# CH32H417 register map
Vendor: WCH Ltd.; File version: 1.2
Registers are 32-bit, read-write, reset 0x0 unless marked. A register's access mark holds for its fields unless they carry their own. Offsets are from the block's base; [hi:lo] are bit positions; {n}, {i} and the like mark numbered series; 'fields as' and 'values as' point back to an identical list.

## FMC
Base 0x40025400
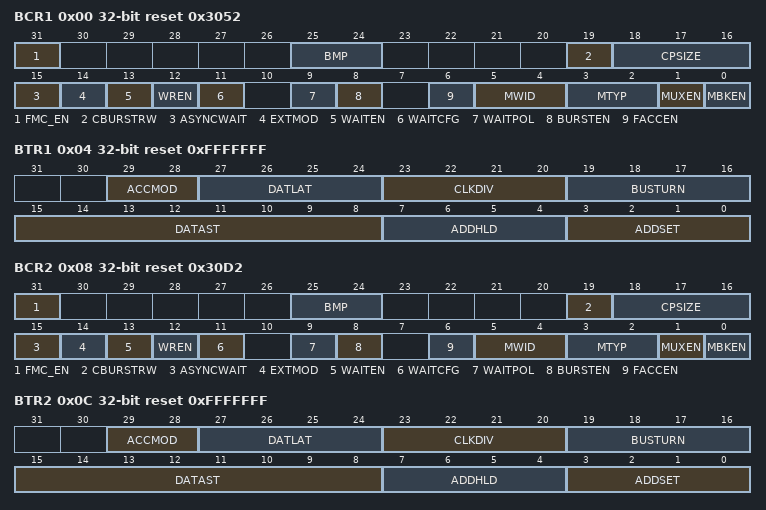
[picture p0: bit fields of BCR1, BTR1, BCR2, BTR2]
0x00 BCR1 reset 0x3052 — This register contains the control information of each memory bank, used for SRAMs, PSRAM and NOR Flash memories.
  [31] FMC_EN — FMC controller Enable
  [25:24] BMP — FMC bank mapping
  [19] CBURSTRW — Write burst enable
  [18:16] CPSIZE — CRAM Page Size
  [15] ASYNCWAIT — Wait signal during asynchronous transfers
  [14] EXTMOD — Extended mode enable
  [13] WAITEN — Wait enable bit
  [12] WREN — Write enable bit
  [11] WAITCFG — Wait timing configuration
  [9] WAITPOL — Wait signal polarity bit
  [8] BURSTEN — Burst enable bit
  [6] FACCEN — Flash access enable
  [5:4] MWID — Memory data bus width Defines the external memory device width, valid for all type of memories.
  [3:2] MTYP — Memory type
  [1] MUXEN — Address/data multiplexing enable bit
  [0] MBKEN — Memory bank enable
0x04 BTR1 reset 0xFFFFFFF — This register contains the control information of each memory bank, used for SRAMs, PSRAM and NOR Flash memories
  [29:28] ACCMOD — Access mode
  [27:24] DATLAT — Data latency for synchronous memory For synchronous access with read write burst mode enabled
  [23:20] CLKDIV — Clock divide ratio (for FMC_CLK signal)
  [19:16] BUSTURN — Bus turnaround phase duration
  [15:8] DATAST — Data-phase duration
  [7:4] ADDHLD — Address-hold phase duration
  [3:0] ADDSET — Address setup phase duration
0x08 BCR2 reset 0x30D2 — This register contains the control information of each memory bank, used for SRAMs, PSRAM and NOR Flash memories.
  [31] FMC_EN — FMC controller Enable
  [25:24] BMP — FMC bank mapping
  [19] CBURSTRW — Write burst enable For PSRAM (CRAM) operating in Burst mode
  [18:16] CPSIZE — CRAM Page Size
  [15] ASYNCWAIT — Wait signal during asynchronous transfers
  [14] EXTMOD — Extended mode enable
  [13] WAITEN — Wait enable bit
  [12] WREN — Write enable bit
  [11] WAITCFG — Wait timing configuration
  [9] WAITPOL — Wait signal polarity bit
  [8] BURSTEN — Burst enable bit
  [6] FACCEN — Flash access enable
  [5:4] MWID — Memory data bus width Defines the external memory device width, valid for all type of memories.
  [3:2] MTYP — Memory type
  [1] MUXEN — Address/data multiplexing enable bit
  [0] MBKEN — Memory bank enable bit
0x0C BTR2 reset 0xFFFFFFF — This register contains the control information of each memory bank, used for SRAMs, PSRAM and NOR Flash memories
  fields as BTR1
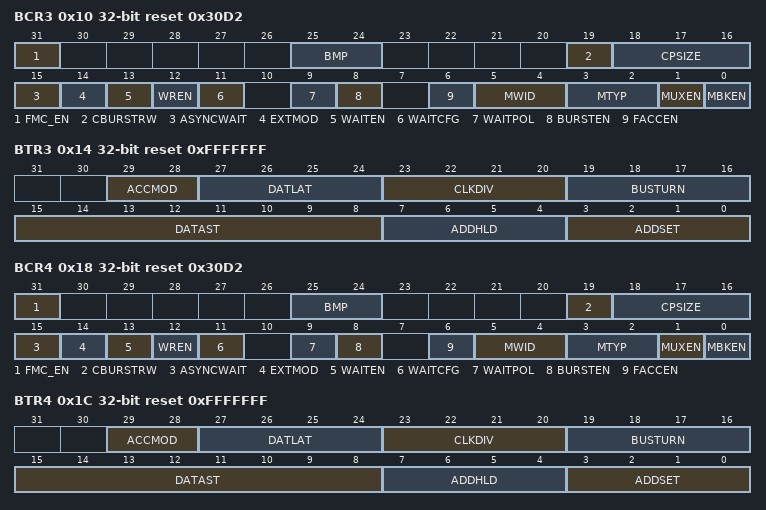
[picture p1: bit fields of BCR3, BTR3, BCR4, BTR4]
0x10 BCR3 reset 0x30D2 — This register contains the control information of each memory bank, used for SRAMs, PSRAM and NOR Flash memories.
  fields as BCR2
0x14 BTR3 reset 0xFFFFFFF — This register contains the control information of each memory bank, used for SRAMs, PSRAM and NOR Flash memories
  fields as BTR1
0x18 BCR4 reset 0x30D2 — This register contains the control information of each memory bank, used for SRAMs, PSRAM and NOR Flash memories.
  fields as BCR2
0x1C BTR4 reset 0xFFFFFFF — This register contains the control information of each memory bank, used for SRAMs, PSRAM and NOR Flash memories
  fields as BTR1
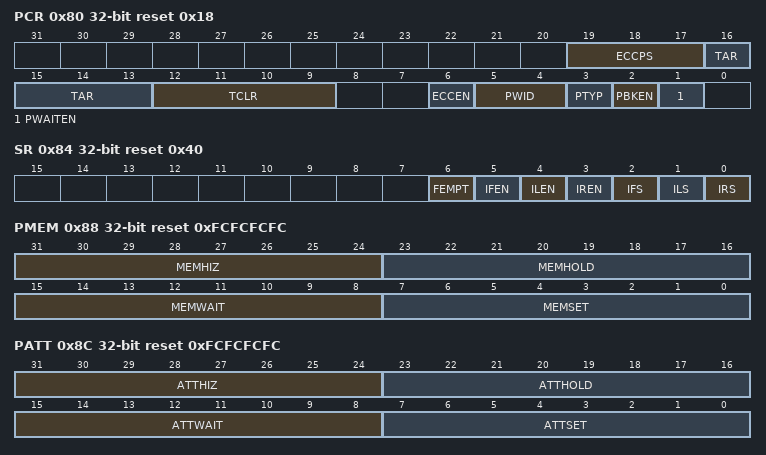
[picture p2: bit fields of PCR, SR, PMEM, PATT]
0x80 PCR reset 0x18 — NAND Flash control registers
  [19:17] ECCPS — ECC page size
  [16:13] TAR — ALE to RE delay
  [12:9] TCLR — CLE to RE delay
  [6] ECCEN — ECC computation logic enable bit
  [5:4] PWID — Data bus width
  [3] PTYP — memory type
  [2] PBKEN — NAND Flash memory bank enable bit
  [1] PWAITEN — Wait feature enable bit
0x84 SR access per field reset 0x40 — This register contains information about the FIFO status and interrupt
  [6] FEMPT ro — FIFO empty
  [5] IFEN rw — Interrupt falling edge detection enable bit
  [4] ILEN rw — Interrupt high-level detection enable bit
  [3] IREN rw — Interrupt rising edge detection enable bit
  [2] IFS rw — Interrupt falling edge status
  [1] ILS rw — Interrupt high-level status
  [0] IRS rw — Interrupt rising edge status
0x88 PMEM reset 0xFCFCFCFC — The FMC_PMEM read/write register contains the timing information for NAND Flash memory bank
  [31:24] MEMHIZ — Common memory x data bus Hi-Z time
  [23:16] MEMHOLD — Common memory hold time
  [15:8] MEMWAIT — Common memory wait time
  [7:0] MEMSET — Common memory x setup time
0x8C PATT reset 0xFCFCFCFC — The FMC_PATT read/write register contains the timing information for NAND Flash memory bank
  [31:24] ATTHIZ — Attribute memory data bus Hi-Z time
  [23:16] ATTHOLD — Attribute memory hold time
  [15:8] ATTWAIT — Attribute memory wait time
  [7:0] ATTSET — Attribute memory setup time
0x94 ECCR ro — This register contain the current error correction code value computed by the ECC computation modules of the FMC NAND controller
  [31:0] ECC — ECC result This field contains the value computed by the ECC computation logic. Table167 describes the contents of these bit fields.
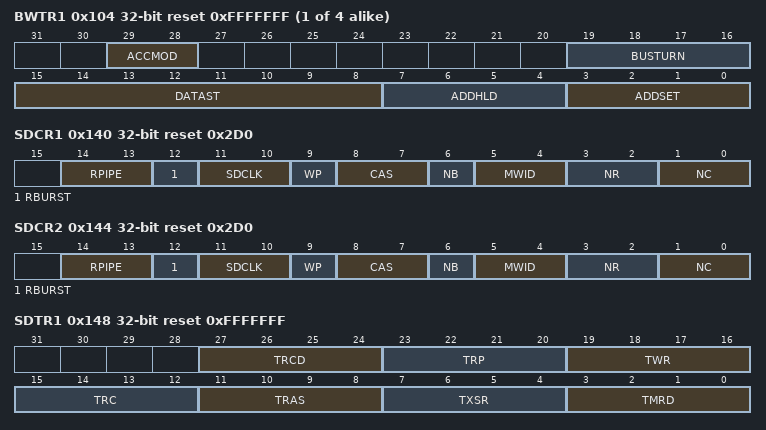
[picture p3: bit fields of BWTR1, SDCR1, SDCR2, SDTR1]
{0xFC+8i} BWTR{i} reset 0xFFFFFFF (i=1..4) — This register contains the control information of each memory bank. It is used for SRAMs, PSRAMs and NOR Flash memories.
  [29:28] ACCMOD — Access mode
  [19:16] BUSTURN — Bus turnaround phase duration
  [15:8] DATAST — Data-phase duration
  [7:4] ADDHLD — Address-hold phase duration
  [3:0] ADDSET — Address setup phase duration
0x140 SDCR1 reset 0x2D0 — This register contains the control parameters for each SDRAM memory bank
  [14:13] RPIPE — Read pipe
  [12] RBURST — Burst read
  [11:10] SDCLK — SDRAM clock configuration
  [9] WP — Write protection This bit enables write mode access to the SDRAM bank.
  [8:7] CAS — CAS Latency This bits sets the SDRAM CAS latency in number of memory clock cycles
  [6] NB — Number of internal banks This bit sets the number of internal banks.
  [5:4] MWID — Memory data bus width. These bits define the memory device width.
  [3:2] NR — Number of row address bits These bits define the number of bits of a row address.
  [1:0] NC — Number of column address bits These bits define the number of bits of a column address.
0x144 SDCR2 reset 0x2D0 — This register contains the control parameters for each SDRAM memory bank
  fields as SDCR1
0x148 SDTR1 reset 0xFFFFFFF — This register contains the timing parameters of each SDRAM bank
  [27:24] TRCD — Row to column delay
  [23:20] TRP — Row precharge delay
  [19:16] TWR — Recovery delay
  [15:12] TRC — Row cycle delay
  [11:8] TRAS — Self refresh time
  [7:4] TXSR — Exit Self-refresh delay
  [3:0] TMRD — Load Mode Register to Active
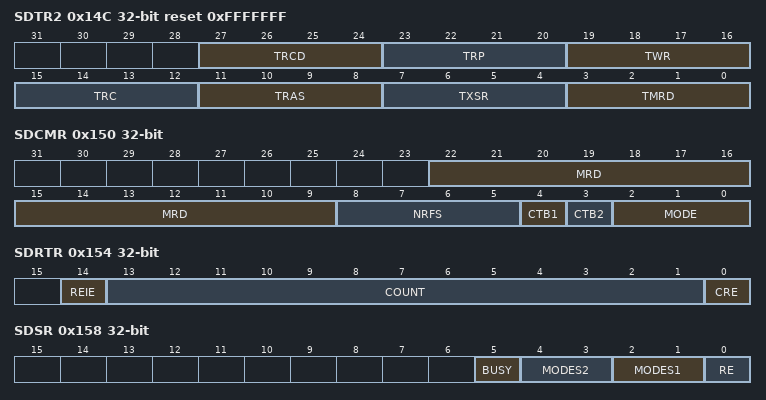
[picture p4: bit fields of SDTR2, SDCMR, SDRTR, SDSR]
0x14C SDTR2 reset 0xFFFFFFF — This register contains the timing parameters of each SDRAM bank
  fields as SDTR1
0x150 SDCMR — This register contains the command issued when the SDRAM device is accessed
  [22:9] MRD — Mode Register definition
  [8:5] NRFS — Number of Auto-refresh
  [4] CTB1 — Command Target Bank 1 This bit indicates whether the command will be issued to SDRAM Bank 1 or not.
  [3] CTB2 — Command Target Bank 2 This bit indicates whether the command will be issued to SDRAM Bank 2 or not.
  [2:0] MODE — Command mode These bits define the command issued to the SDRAM device.
0x154 SDRTR access per field — This register sets the refresh rate in number of SDCLK clock cycles between the refresh cycles by configuring the Refresh Timer Count value
  [14] REIE rw — RES Interrupt Enable
  [13:1] COUNT rw — Refresh Timer Count
  [0] CRE wo — Clear Refresh error flag
0x158 SDSR ro — SDRAM Status register
  [5] BUSY
  [4:3] MODES2 — Status Mode for Bank 2 These bits define the Status Mode of SDRAM Bank 2.
  [2:1] MODES1 — Status Mode for Bank 1 These bits define the Status Mode of SDRAM Bank 1.
  [0] RE — Refresh error flag An interrupt is generated if REIE = 1 and RE = 1
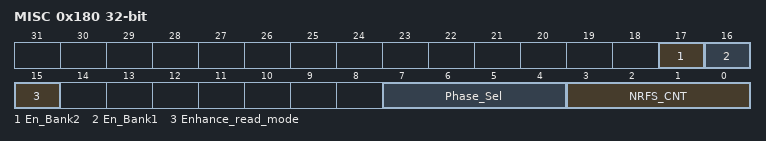
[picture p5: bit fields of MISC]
0x180 MISC — SDRAM custom registers
  [17] En_Bank2 — Enable SDRAM2
  [16] En_Bank1 — Enable SDRAM1
  [15] Enhance_read_mode — Read enhancement/prefetch mode
  [7:4] Phase_Sel — Phase offset of the output SDR_CLK
  [3:0] NRFS_CNT — Define the number of times the controller self-refreshes each time
